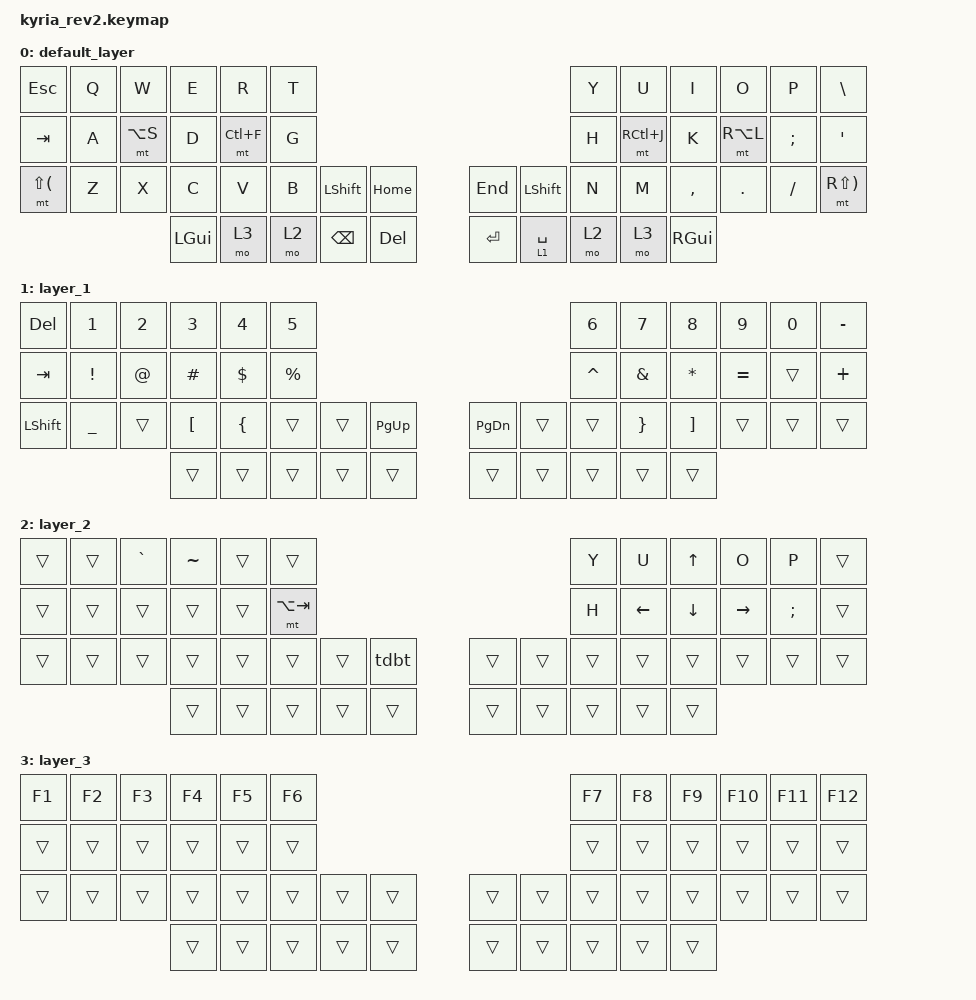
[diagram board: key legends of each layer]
/*
 * Copyright (c) 2020 The ZMK Contributors
 *
 * SPDX-License-Identifier: MIT
 */

#include <behaviors.dtsi>
#include <dt-bindings/zmk/keys.h>
#include <dt-bindings/zmk/bt.h>

#define BASE 0
#define ONE  1
#define TWO  2
#define THREE 3

&mt {
    retro-tap;
    flavor = "tap-preferred";
    tapping-term-ms = <200>;
};
&lt {
    retro-tap;
    flavor = "tap-preferred";
    tapping-term-ms = <200>;
};

&caps_word {
    continue-list = <UNDERSCORE MINUS BACKSPACE DELETE>;
    mods = <MOD_LSFT | MOD_RSFT>;
};

/ {
    behaviors {
        tdbt: tap_dance_0 {
            compatible = "zmk,behavior-tap-dance";
            label = "TAP_DANCE_0";
            #binding-cells = <0>;
            tapping-term-ms = <170>;
            bindings = <&bt BT_SEL 0>, <&bt BT_SEL 1>, <&bt BT_SEL 2>, <&bt BT_SEL 4>, <&bt BT_SEL 5>;
        };
    };

/ {
	keymap {
		compatible = "zmk,keymap";

		default_layer {
// ---------------------------------------------------------------------------------------------------------------------------------
// |  ESC  |  Q  |  W  |  E   |  R   |  T   |                                          |  Y   |  U    |  I    |  O   |   P   |   \  |
// |  TAB  |  A  |LA(S)|  D   | LC(F)|  G   |                                          |  H   |LC(J)  |  K    |RA(L) |   ;   |   '  |
// | CADET |  Z  |  X  |  C   |  V   |  B   |         |   HOME  |  |   END   |         |  N   |  M    |  ,    |  .   |   /   | CADET|
//                     | GUI  |  MO3 | MO2  |   BSPC  |   DEL   |  |   RET   |LT(SPACE)| MO2  | MO3   | GUI   |
			bindings = <
	&kp ESC   &kp Q &kp W &kp E &kp R &kp T                                        &kp Y &kp U  &kp I     &kp O   &kp P    &kp BSLH
	&kp TAB   &kp A &mt LA(S) &kp D &mt LC(F) &kp G                                &kp H &mt RC(J)  &kp K  &mt RA(L) &kp SEMI &kp SQT
	&mt LS(LPAR) &kp Z &kp X &kp C &kp V &kp B &kp LSHFT &kp HOME        &kp END &kp LSHFT &kp N &kp M  &kp COMMA &kp DOT &kp FSLH &mt RS(RPAR)
	                 &kp LGUI &mo 3 &mo 2 &kp BSPC &kp DEL        &kp RET  &lt 1 SPACE  &mo 2 &mo 3 &kp RGUI
			>;

			
		};

		layer_1 {
// ---------------------------------------------------------------------------------------------------------------------------------
// |  DEL  |  1  |  2  |  3   |  4   |  5   |                                          |  6   |  7    |  8    |  9   |   0   |   -  |
// |       |  !  |  @  |  #   |  $   |  %   |                                          |  ^   |  &    |  *    |  =   |       |      |
// |       |  _  |     |  [   |  {   |      |         | PG UP   |  | PG DN   |         |      |  }    |  ]    |      |       |      |
//                     | GUI  |  MO3 | MO2  |   BSPC  |   DEL   |  |   RET   |LT(SPACE)| MO2  | MO3  | GUI   |
			bindings = <
	&kp DEL   &kp N1 &kp N2 &kp N3 &kp N4 &kp N5                                   &kp N6 &kp N7  &kp N8  &kp N9   &kp N0 &kp MINUS
	&kp TAB   &kp EXCL &kp AT &kp HASH &kp DLLR &kp PRCNT                          &kp CARET &kp AMPS  &kp STAR   &kp EQUAL   &trans &kp PLUS
	&kp LSHFT &kp UNDER &trans &kp LBKT &kp LBRC &trans &trans &kp PG_UP &kp PG_DN &trans &trans &kp RBRC  &kp RBKT &trans &trans &trans
	                 &trans &trans &trans &trans &trans          &trans  &trans  &trans &trans &trans
			>;

			
		};

		layer_2 {
// ---------------------------------------------------------------------------------------------------------------------------------
// |       |     |     |      |      |      |                                          |      |       |  UP   |      |       |      |
// |       |     |     |      |      |      |                                          |      | LEFT  |  DOWN |RIGHT |       |      |
// |       |     |     |      |      |      |         |BLUETOOTH|  |         |         |      |       |       |      |       |      |
//                     | GUI  |  MO3 | MO2  |   BSPC  |   DEL   |  |   RET   |LT(SPACE)| MO2  | MO3   | GUI   |
			bindings = <
	&trans   &trans &kp GRAVE &kp TILDE &trans &trans                              &kp Y &kp U  &kp UP     &kp O   &kp P    &trans
	&trans   &trans &trans &trans &trans &mt LA(TAB)                               &kp H &kp LEFT  &kp DOWN     &kp RIGHT   &kp SEMI &trans
	&trans &trans &trans &trans &trans &trans &trans &tdbt            &trans &trans &trans &trans &trans &trans &trans &trans
	                 &trans &trans &trans &trans &trans          &trans  &trans  &trans &trans &trans
			>;

			
		};

		layer_3 {
// ---------------------------------------------------------------------------------------------------------------------------------
// |  F1   |  F2 |  F3 |  F4  |  F5  |  F6  |                                          | F7   |   F8  |   F9  |  F10 |   F11 | F12  |
// |       |     |     |      |      |      |                                          |      |       |       |      |       |      |
// |       |     |     |      |      |      |         |         |  |         |         |      |       |       |      |       |      |
//                     | GUI  |  MO3 | MO2  |   BSPC  |   DEL   |  |   RET   |LT(SPACE)| MO2  | MO3   | GUI   |
			bindings = <
	&kp F1   &kp F2 &kp F3 &kp F4 &kp F5 &kp F6                                    &kp F7 &kp F8  &kp F9     &kp F10   &kp F11    &kp F12
	&trans   &trans &trans &trans &trans &trans                                    &trans &trans  &trans     &trans   &trans &trans
	&trans &trans &trans &trans &trans &trans &trans &trans            &trans &trans &trans &trans  &trans &trans &trans &trans
	                 &trans &trans &trans &trans &trans          &trans  &trans  &trans &trans &trans
			>;

			
		};

	};
};
